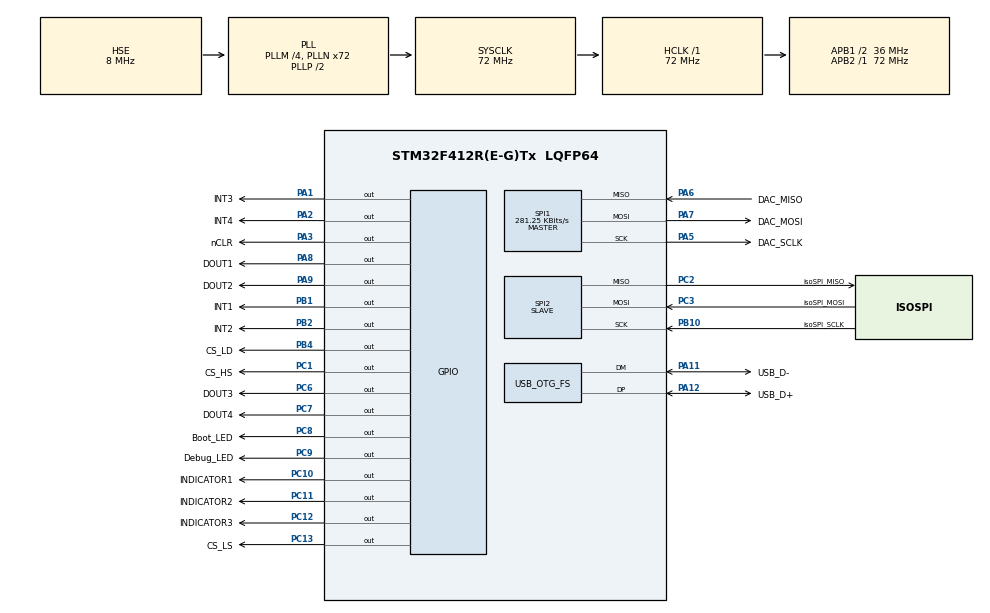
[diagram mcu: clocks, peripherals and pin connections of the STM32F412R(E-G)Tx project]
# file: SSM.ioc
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FREERTOS.Tasks01=defaultTask,24,512,StartDefaultTask,Default,NULL,Dynamic,NULL,NULL
Mcu.Family=STM32F4
Mcu.Name=STM32F412R(E-G)Tx
Mcu.Package=LQFP64
NVIC.OTG_FS_IRQn=true\:5\:0\:false\:false\:true\:true\:false\:true\:true
NVIC.PriorityGroup=NVIC_PRIORITYGROUP_4
NVIC.SPI1_IRQn=true\:5\:0\:false\:false\:true\:true\:true\:true\:true
NVIC.SPI2_IRQn=true\:5\:0\:false\:false\:true\:true\:true\:true\:true
PA1.GPIO_Label=INT3
PA1.Signal=GPIO_Output
PA11.GPIO_Label=USB_D-
PA11.Mode=Device_Only
PA11.Signal=USB_OTG_FS_DM
PA12.GPIO_Label=USB_D+
PA12.Mode=Device_Only
PA12.Signal=USB_OTG_FS_DP
PA13.GPIO_Label=SWDIO
PA13.Mode=Trace_Asynchronous_SW
PA13.Signal=SYS_JTMS-SWDIO
PA14.GPIO_Label=SWCLK
PA14.Mode=Trace_Asynchronous_SW
PA14.Signal=SYS_JTCK-SWCLK
PA2.GPIO_Label=INT4
PA2.Signal=GPIO_Output
PA3.GPIO_Label=nCLR
PA3.PinState=GPIO_PIN_SET
PA3.Signal=GPIO_Output
PA5.GPIO_Label=DAC_SCLK
PA5.Mode=Full_Duplex_Master
PA5.Signal=SPI1_SCK
PA6.GPIO_Label=DAC_MISO
PA6.Mode=Full_Duplex_Master
PA6.Signal=SPI1_MISO
PA7.GPIO_Label=DAC_MOSI
PA7.Mode=Full_Duplex_Master
PA7.Signal=SPI1_MOSI
PA8.GPIO_Label=DOUT1
PA8.Signal=GPIO_Output
PA9.GPIO_Label=DOUT2
PA9.Signal=GPIO_Output
PB1.GPIO_Label=INT1
PB1.Signal=GPIO_Output
PB10.GPIO_Label=isoSPI_SCLK
PB10.Mode=Full_Duplex_Slave
PB10.Signal=SPI2_SCK
PB2.GPIO_Label=INT2
PB2.Signal=GPIO_Output
PB3.GPIO_Label=SWO
PB3.Mode=Trace_Asynchronous_SW
PB3.Signal=SYS_JTDO-SWO
PB4.GPIO_Label=CS_LD
PB4.GPIO_Speed=GPIO_SPEED_FREQ_HIGH
PB4.PinState=GPIO_PIN_SET
PB4.Signal=GPIO_Output
PC1.GPIO_Label=CS_HS
PC1.Signal=GPIO_Output
PC10.GPIO_Label=INDICATOR1
PC10.Signal=GPIO_Output
PC11.GPIO_Label=INDICATOR2
PC11.Signal=GPIO_Output
PC12.GPIO_Label=INDICATOR3
PC12.Signal=GPIO_Output
PC13.GPIO_Label=CS_LS
PC13.Signal=GPIO_Output
PC2.GPIO_Label=isoSPI_MISO
PC2.Mode=Full_Duplex_Slave
PC2.Signal=SPI2_MISO
PC3.GPIO_Label=isoSPI_MOSI
PC3.Mode=Full_Duplex_Slave
PC3.Signal=SPI2_MOSI
PC6.GPIO_Label=DOUT3
PC6.Signal=GPIO_Output
PC7.GPIO_Label=DOUT4
PC7.Signal=GPIO_Output
PC8.GPIO_Label=Boot_LED
PC8.Signal=GPIO_Output
PC9.GPIO_Label=Debug_LED
PC9.Signal=GPIO_Output
PH0\ -\ OSC_IN.Mode=HSE-External-Oscillator
PH0\ -\ OSC_IN.Signal=RCC_OSC_IN
PH1\ -\ OSC_OUT.Mode=HSE-External-Oscillator
PH1\ -\ OSC_OUT.Signal=RCC_OSC_OUT
ProjectManager.HeapSize=0x200
ProjectManager.StackSize=0x400
ProjectManager.TargetToolchain=EWARM V8.50
RCC.AHBFreq_Value=72000000
RCC.APB1CLKDivider=RCC_HCLK_DIV2
RCC.APB1Freq_Value=36000000
RCC.APB1TimFreq_Value=72000000
RCC.APB2Freq_Value=72000000
RCC.APB2TimFreq_Value=72000000
RCC.CortexFreq_Value=72000000
RCC.HCLKFreq_Value=72000000
RCC.HSE_VALUE=8000000
RCC.PLLI2SM=4
RCC.PLLI2SQ=8
RCC.PLLM=4
RCC.PLLN=72
RCC.PLLQ=3
RCC.SYSCLKFreq_VALUE=72000000
RCC.SYSCLKSource=RCC_SYSCLKSOURCE_PLLCLK
RCC.USBFreq_Value=48000000
RCC.VCOOutputFreq_Value=144000000
SPI1.BaudRatePrescaler=SPI_BAUDRATEPRESCALER_256
SPI1.CalculateBaudRate=281.25 KBits/s
SPI1.Direction=SPI_DIRECTION_2LINES
SPI1.Mode=SPI_MODE_MASTER
SPI1.VirtualType=VM_MASTER
SPI2.Direction=SPI_DIRECTION_2LINES
SPI2.Mode=SPI_MODE_SLAVE
SPI2.VirtualType=VM_SLAVE
USB_DEVICE.CLASS_NAME_FS=CDC
USB_DEVICE.MANUFACTURER_STRING=ubc_formula_electric
USB_DEVICE.PRODUCT_STRING_CDC_FS=ssm
USB_DEVICE.VirtualMode=Cdc
USB_DEVICE.VirtualModeFS=Cdc_FS
USB_OTG_FS.VirtualMode=Device_Only
VP_FREERTOS_VS_CMSIS_V2.Mode=CMSIS_V2
VP_USB_DEVICE_VS_USB_DEVICE_CDC_FS.Mode=CDC_FS
board=custom

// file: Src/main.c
/* USER CODE BEGIN Header */
/**
 ******************************************************************************
 * @file           : main.c
 * @brief          : Main program body
 ******************************************************************************
 * @attention
 *
 * Copyright (c) 2024 STMicroelectronics.
 * All rights reserved.
 *
 * This software is licensed under terms that can be found in the LICENSE file
 * in the root directory of this software component.
 * If no LICENSE file comes with this software, it is provided AS-IS.
 *
 ******************************************************************************
 */
/* USER CODE END Header */
#include "main.h"
#include "cmsis_os.h"
#include "usb_device.h"

/* USER CODE BEGIN Includes */
#include "hw/chimera_v2.h"
#include "hw/chimeraConfig_v2.h"
#include "shared.pb.h"
#include "hw/usb.h"
#include "hw/gpios.h"
#include "io/log.h"

/* USER CODE END Includes */

SPI_HandleTypeDef hspi1;
SPI_HandleTypeDef hspi2;

/* Definitions for defaultTask */
osThreadId_t         defaultTaskHandle;
const osThreadAttr_t defaultTask_attributes = {
    .name       = "defaultTask",
    .stack_size = 512 * 4,
    .priority   = (osPriority_t)osPriorityNormal,
};

void        SystemClock_Config(void);
static void MX_GPIO_Init(void);
static void MX_SPI1_Init(void);
static void MX_SPI2_Init(void);
void        StartDefaultTask(void *argument);

int main(void)
{

    /* MCU Configuration--------------------------------------------------------*/

    /* Reset of all peripherals, Initializes the Flash interface and the Systick. */
    HAL_Init();

    /* Configure the system clock */
    SystemClock_Config();

    /* Initialize all configured peripherals */
    MX_GPIO_Init();
    MX_SPI1_Init();
    MX_SPI2_Init();

    /* Init scheduler */
    osKernelInitialize();

    /* USER CODE BEGIN RTOS_QUEUES */
    ASSERT_EXIT_OK(hw_usb_init());
    /* USER CODE END RTOS_QUEUES */

    /* Create the thread(s) */
    /* creation of defaultTask */
    defaultTaskHandle = osThreadNew(StartDefaultTask, NULL, &defaultTask_attributes);

    /* Start scheduler */
    osKernelStart();

    /* We should never get here as control is now taken by the scheduler */

    /* Infinite loop */
    while (1)
    {

    }
}

void SystemClock_Config(void)
{
    RCC_OscInitTypeDef RCC_OscInitStruct = { 0 };
    RCC_ClkInitTypeDef RCC_ClkInitStruct = { 0 };

    /** Configure the main internal regulator output voltage
     */
    __HAL_RCC_PWR_CLK_ENABLE();
    __HAL_PWR_VOLTAGESCALING_CONFIG(PWR_REGULATOR_VOLTAGE_SCALE1);

    /** Initializes the RCC Oscillators according to the specified parameters
     * in the RCC_OscInitTypeDef structure.
     */
    RCC_OscInitStruct.OscillatorType = RCC_OSCILLATORTYPE_HSE;
    RCC_OscInitStruct.HSEState       = RCC_HSE_ON;
    RCC_OscInitStruct.PLL.PLLState   = RCC_PLL_ON;
    RCC_OscInitStruct.PLL.PLLSource  = RCC_PLLSOURCE_HSE;
    RCC_OscInitStruct.PLL.PLLM       = 4;
    RCC_OscInitStruct.PLL.PLLN       = 72;
    RCC_OscInitStruct.PLL.PLLP       = RCC_PLLP_DIV2;
    RCC_OscInitStruct.PLL.PLLQ       = 3;
    RCC_OscInitStruct.PLL.PLLR       = 2;
    if (HAL_RCC_OscConfig(&RCC_OscInitStruct) != HAL_OK)
    {
        Error_Handler();
    }

    /** Initializes the CPU, AHB and APB buses clocks
     */
    RCC_ClkInitStruct.ClockType = RCC_CLOCKTYPE_HCLK | RCC_CLOCKTYPE_SYSCLK | RCC_CLOCKTYPE_PCLK1 | RCC_CLOCKTYPE_PCLK2;
    RCC_ClkInitStruct.SYSCLKSource   = RCC_SYSCLKSOURCE_PLLCLK;
    RCC_ClkInitStruct.AHBCLKDivider  = RCC_SYSCLK_DIV1;
    RCC_ClkInitStruct.APB1CLKDivider = RCC_HCLK_DIV2;
    RCC_ClkInitStruct.APB2CLKDivider = RCC_HCLK_DIV1;

    if (HAL_RCC_ClockConfig(&RCC_ClkInitStruct, FLASH_LATENCY_2) != HAL_OK)
    {
        Error_Handler();
    }
}

static void MX_SPI1_Init(void)
{

    /* SPI1 parameter configuration*/
    hspi1.Instance               = SPI1;
    hspi1.Init.Mode              = SPI_MODE_MASTER;
    hspi1.Init.Direction         = SPI_DIRECTION_2LINES;
    hspi1.Init.DataSize          = SPI_DATASIZE_8BIT;
    hspi1.Init.CLKPolarity       = SPI_POLARITY_LOW;
    hspi1.Init.CLKPhase          = SPI_PHASE_1EDGE;
    hspi1.Init.NSS               = SPI_NSS_SOFT;
    hspi1.Init.BaudRatePrescaler = SPI_BAUDRATEPRESCALER_256;
    hspi1.Init.FirstBit          = SPI_FIRSTBIT_MSB;
    hspi1.Init.TIMode            = SPI_TIMODE_DISABLE;
    hspi1.Init.CRCCalculation    = SPI_CRCCALCULATION_DISABLE;
    hspi1.Init.CRCPolynomial     = 10;
    if (HAL_SPI_Init(&hspi1) != HAL_OK)
    {
        Error_Handler();
    }
}

static void MX_SPI2_Init(void)
{

    /* SPI2 parameter configuration*/
    hspi2.Instance            = SPI2;
    hspi2.Init.Mode           = SPI_MODE_SLAVE;
    hspi2.Init.Direction      = SPI_DIRECTION_2LINES;
    hspi2.Init.DataSize       = SPI_DATASIZE_8BIT;
    hspi2.Init.CLKPolarity    = SPI_POLARITY_LOW;
    hspi2.Init.CLKPhase       = SPI_PHASE_1EDGE;
    hspi2.Init.NSS            = SPI_NSS_SOFT;
    hspi2.Init.FirstBit       = SPI_FIRSTBIT_MSB;
    hspi2.Init.TIMode         = SPI_TIMODE_DISABLE;
    hspi2.Init.CRCCalculation = SPI_CRCCALCULATION_DISABLE;
    hspi2.Init.CRCPolynomial  = 10;
    if (HAL_SPI_Init(&hspi2) != HAL_OK)
    {
        Error_Handler();
    }
}

static void MX_GPIO_Init(void)
{
    GPIO_InitTypeDef GPIO_InitStruct = { 0 };

    /* GPIO Ports Clock Enable */
    __HAL_RCC_GPIOC_CLK_ENABLE();
    __HAL_RCC_GPIOH_CLK_ENABLE();
    __HAL_RCC_GPIOA_CLK_ENABLE();
    __HAL_RCC_GPIOB_CLK_ENABLE();

    /*Configure GPIO pin Output Level */
    HAL_GPIO_WritePin(
        GPIOC,
        CS_LS_Pin | CS_HS_Pin | DOUT3_Pin | DOUT4_Pin | Boot_LED_Pin | Debug_LED_Pin | INDICATOR1_Pin | INDICATOR2_Pin |
            INDICATOR3_Pin,
        GPIO_PIN_RESET);

    /*Configure GPIO pin Output Level */
    HAL_GPIO_WritePin(GPIOA, INT3_Pin | INT4_Pin | DOUT1_Pin | DOUT2_Pin, GPIO_PIN_RESET);

    /*Configure GPIO pin Output Level */
    HAL_GPIO_WritePin(nCLR_GPIO_Port, nCLR_Pin, GPIO_PIN_SET);

    /*Configure GPIO pin Output Level */
    HAL_GPIO_WritePin(GPIOB, INT1_Pin | INT2_Pin, GPIO_PIN_RESET);

    /*Configure GPIO pin Output Level */
    HAL_GPIO_WritePin(CS_LD_GPIO_Port, CS_LD_Pin, GPIO_PIN_SET);

    /*Configure GPIO pins : CS_LS_Pin CS_HS_Pin DOUT3_Pin DOUT4_Pin
                             Boot_LED_Pin Debug_LED_Pin INDICATOR1_Pin INDICATOR2_Pin
                             INDICATOR3_Pin */
    GPIO_InitStruct.Pin = CS_LS_Pin | CS_HS_Pin | DOUT3_Pin | DOUT4_Pin | Boot_LED_Pin | Debug_LED_Pin |
                          INDICATOR1_Pin | INDICATOR2_Pin | INDICATOR3_Pin;
    GPIO_InitStruct.Mode  = GPIO_MODE_OUTPUT_PP;
    GPIO_InitStruct.Pull  = GPIO_NOPULL;
    GPIO_InitStruct.Speed = GPIO_SPEED_FREQ_LOW;
    HAL_GPIO_Init(GPIOC, &GPIO_InitStruct);

    /*Configure GPIO pins : INT3_Pin INT4_Pin nCLR_Pin DOUT1_Pin
                             DOUT2_Pin */
    GPIO_InitStruct.Pin   = INT3_Pin | INT4_Pin | nCLR_Pin | DOUT1_Pin | DOUT2_Pin;
    GPIO_InitStruct.Mode  = GPIO_MODE_OUTPUT_PP;
    GPIO_InitStruct.Pull  = GPIO_NOPULL;
    GPIO_InitStruct.Speed = GPIO_SPEED_FREQ_LOW;
    HAL_GPIO_Init(GPIOA, &GPIO_InitStruct);

    /*Configure GPIO pins : INT1_Pin INT2_Pin */
    GPIO_InitStruct.Pin   = INT1_Pin | INT2_Pin;
    GPIO_InitStruct.Mode  = GPIO_MODE_OUTPUT_PP;
    GPIO_InitStruct.Pull  = GPIO_NOPULL;
    GPIO_InitStruct.Speed = GPIO_SPEED_FREQ_LOW;
    HAL_GPIO_Init(GPIOB, &GPIO_InitStruct);

    /*Configure GPIO pin : CS_LD_Pin */
    GPIO_InitStruct.Pin   = CS_LD_Pin;
    GPIO_InitStruct.Mode  = GPIO_MODE_OUTPUT_PP;
    GPIO_InitStruct.Pull  = GPIO_NOPULL;
    GPIO_InitStruct.Speed = GPIO_SPEED_FREQ_HIGH;
    HAL_GPIO_Init(CS_LD_GPIO_Port, &GPIO_InitStruct);

}

void StartDefaultTask(void *argument)
{
    /* init code for USB_DEVICE */
    MX_USB_DEVICE_Init();
    /* USER CODE BEGIN 5 */

    // Invoke Chimera V2.
    hw_chimera_v2_task(&chimera_v2_config);

    /* USER CODE END 5 */
}

void Error_Handler(void)
{
    __disable_irq();
    while (1)
    {
    }
}
